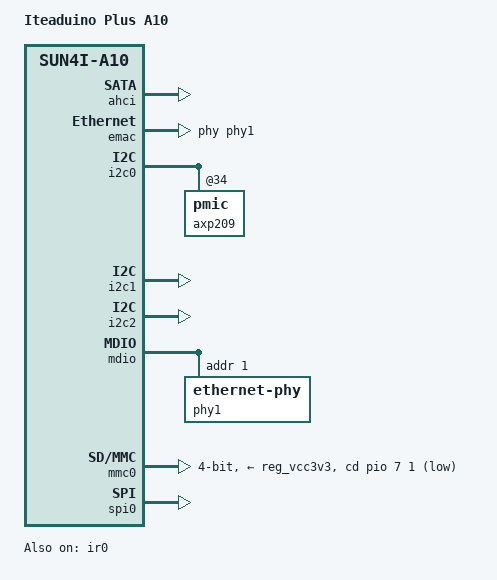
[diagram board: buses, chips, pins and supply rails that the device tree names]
/dts-v1/;
#include "sun4i-a10.dtsi"
#include "sunxi-itead-core-common.dtsi"
/ {
	model = "Iteaduino Plus A10";
	compatible = "itead,iteaduino-plus-a10", "allwinner,sun4i-a10";
};
&ahci {
	target-supply = <&reg_ahci_5v>;
	status = "okay";
};
&emac {
	pinctrl-names = "default";
	pinctrl-0 = <&emac_pins>;
	phy-handle = <&phy1>;
	status = "okay";
};
&emac_sram {
	status = "okay";
};
&i2c0 {
	pinctrl-names = "default";
	pinctrl-0 = <&i2c0_pins>;
	axp209: pmic@34 {
		interrupts = <0>;
	};
};
&i2c1 {
	pinctrl-names = "default";
	pinctrl-0 = <&i2c1_pins>;
	status = "okay";
};
&i2c2 {
	pinctrl-names = "default";
	pinctrl-0 = <&i2c2_pins>;
	status = "okay";
};
&ir0 {
	pinctrl-names = "default";
	pinctrl-0 = <&ir0_rx_pins>;
	status = "okay";
};
&mdio {
	status = "okay";
	phy1: ethernet-phy@1 {
		reg = <1>;
	};
};
&mmc0 {
	pinctrl-names = "default";
	pinctrl-0 = <&mmc0_pins>;
	vmmc-supply = <&reg_vcc3v3>;
	bus-width = <4>;
	cd-gpios = <&pio 7 1 GPIO_ACTIVE_LOW>;  
	status = "okay";
};
&reg_ahci_5v {
	status = "okay";
};
&spi0 {
	pinctrl-names = "default";
	pinctrl-0 = <&spi0_pi_pins>,
		    <&spi0_cs0_pi_pin>;
	status = "okay";
};
&uart0 {
	pinctrl-0 = <&uart0_pb_pins>;
};
